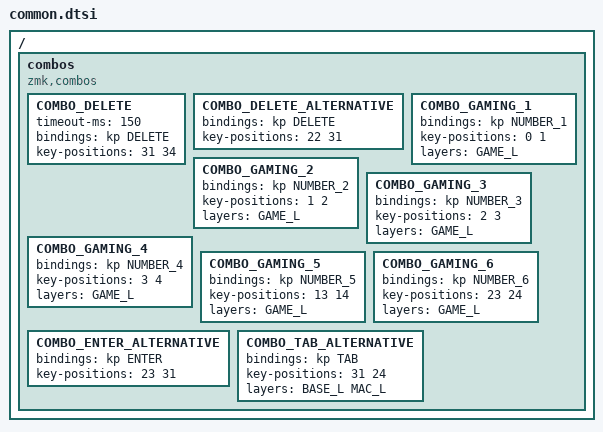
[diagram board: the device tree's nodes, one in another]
/ {
	    combos {
        compatible = "zmk,combos";
// ┌─────┬─────┬─────┬─────┬─────┐┌─────┬─────┬─────┬─────┬─────┐
// │  0  │  1  │  2  │  3  │  4  ││  5  │  6  │  7  │  8  │  9  │
// │─────┼─────┼─────┼─────┼─────┤│─────┼─────┼─────┼─────┼─────┤
// │  10 │  11 │  12 │  13 │  14 ││  15 │  16 │  17 │  18 │  19 │
// │─────┼─────┼─────┼─────┼─────┤│─────┤─────┼─────┼─────┼─────┼
// │  20 │  21 │  22 │  23 │  24 ││  25 │  26 │  27 │  28 │  29 │
// └─────┴─────┼─────┼─────┤─────┤│─────│─────┼─────┼─────┴─────┴
//             │  30 │  31 │  32 ││  33 │  34 │  35 │
//             └─────┼─────┼─────││─────│─────┴─────┘
//                     ENCL│  36 ││  37 │ENCR
//                         ┴─────┴┴─────┘                        
        COMBO_DELETE {
            timeout-ms = <150>;
            bindings = <&kp DELETE>;
            key-positions = <31 34>;
        };


// ┌─────┬─────┬─────┬─────┬─────┐┌─────┬─────┬─────┬─────┬─────┐
// │  0  │  1  │  2  │  3  │  4  ││  5  │  6  │  7  │  8  │  9  │
// │─────┼─────┼─────┼─────┼─────┤│─────┼─────┼─────┼─────┼─────┤
// │  10 │  11 │  12 │  13 │  14 ││  15 │  16 │  17 │  18 │  19 │
// │─────┼─────┼─────┼─────┼─────┤│─────┤─────┼─────┼─────┼─────┼
// │  20 │  21 │  22 │  23 │  24 ││  25 │  26 │  27 │  28 │  29 │
// └─────┴─────┼─────┼─────┤─────┤│─────│─────┼─────┼─────┴─────┴
//             │  30 │  31 │  32 ││  33 │  34 │  35 │
//             └─────┼─────┼─────││─────│─────┴─────┘
//                     ENCL│  36 ││  37 │ENCR
//                         ┴─────┴┴─────┘            
        COMBO_DELETE_ALTERNATIVE {
            bindings = <&kp DELETE>;
            key-positions = <22 31>;
        };

// ┌─────┬─────┬─────┬─────┬─────┐┌─────┬─────┬─────┬─────┬─────┐
// │  0  │  1  │  2  │  3  │  4  ││  5  │  6  │  7  │  8  │  9  │
// │─────┼─────┼─────┼─────┼─────┤│─────┼─────┼─────┼─────┼─────┤
// │  10 │  11 │  12 │  13 │  14 ││  15 │  16 │  17 │  18 │  19 │
// │─────┼─────┼─────┼─────┼─────┤│─────┤─────┼─────┼─────┼─────┼
// │  20 │  21 │  22 │  23 │  24 ││  25 │  26 │  27 │  28 │  29 │
// └─────┴─────┼─────┼─────┤─────┤│─────│─────┼─────┼─────┴─────┴
//             │  30 │  31 │  32 ││  33 │  34 │  35 │
//             └─────┼─────┼─────││─────│─────┴─────┘
//                     ENCL│  36 ││  37 │ENCR
//                         ┴─────┴┴─────┘            
        COMBO_GAMING_1 {
            bindings = <&kp NUMBER_1>;
            key-positions = <0 1>;
            layers = <GAME_L>;
        };

// ┌─────┬─────┬─────┬─────┬─────┐┌─────┬─────┬─────┬─────┬─────┐
// │  0  │  1  │  2  │  3  │  4  ││  5  │  6  │  7  │  8  │  9  │
// │─────┼─────┼─────┼─────┼─────┤│─────┼─────┼─────┼─────┼─────┤
// │  10 │  11 │  12 │  13 │  14 ││  15 │  16 │  17 │  18 │  19 │
// │─────┼─────┼─────┼─────┼─────┤│─────┤─────┼─────┼─────┼─────┼
// │  20 │  21 │  22 │  23 │  24 ││  25 │  26 │  27 │  28 │  29 │
// └─────┴─────┼─────┼─────┤─────┤│─────│─────┼─────┼─────┴─────┴
//             │  30 │  31 │  32 ││  33 │  34 │  35 │
//             └─────┼─────┼─────││─────│─────┴─────┘
//                     ENCL│  36 ││  37 │ENCR
//                         ┴─────┴┴─────┘            
        COMBO_GAMING_2 {
            bindings = <&kp NUMBER_2>;
            key-positions = <1 2>;
            layers = <GAME_L>;
        };

// ┌─────┬─────┬─────┬─────┬─────┐┌─────┬─────┬─────┬─────┬─────┐
// │  0  │  1  │  2  │  3  │  4  ││  5  │  6  │  7  │  8  │  9  │
// │─────┼─────┼─────┼─────┼─────┤│─────┼─────┼─────┼─────┼─────┤
// │  10 │  11 │  12 │  13 │  14 ││  15 │  16 │  17 │  18 │  19 │
// │─────┼─────┼─────┼─────┼─────┤│─────┤─────┼─────┼─────┼─────┼
// │  20 │  21 │  22 │  23 │  24 ││  25 │  26 │  27 │  28 │  29 │
// └─────┴─────┼─────┼─────┤─────┤│─────│─────┼─────┼─────┴─────┴
//             │  30 │  31 │  32 ││  33 │  34 │  35 │
//             └─────┼─────┼─────││─────│─────┴─────┘
//                     ENCL│  36 ││  37 │ENCR
//                         ┴─────┴┴─────┘            

        COMBO_GAMING_3 {
            bindings = <&kp NUMBER_3>;
            key-positions = <2 3>;
            layers = <GAME_L>;
        };

// ┌─────┬─────┬─────┬─────┬─────┐┌─────┬─────┬─────┬─────┬─────┐
// │  0  │  1  │  2  │  3  │  4  ││  5  │  6  │  7  │  8  │  9  │
// │─────┼─────┼─────┼─────┼─────┤│─────┼─────┼─────┼─────┼─────┤
// │  10 │  11 │  12 │  13 │  14 ││  15 │  16 │  17 │  18 │  19 │
// │─────┼─────┼─────┼─────┼─────┤│─────┤─────┼─────┼─────┼─────┼
// │  20 │  21 │  22 │  23 │  24 ││  25 │  26 │  27 │  28 │  29 │
// └─────┴─────┼─────┼─────┤─────┤│─────│─────┼─────┼─────┴─────┴
//             │  30 │  31 │  32 ││  33 │  34 │  35 │
//             └─────┼─────┼─────││─────│─────┴─────┘
//                     ENCL│  36 ││  37 │ENCR
//                         ┴─────┴┴─────┘            
        COMBO_GAMING_4 {
            bindings = <&kp NUMBER_4>;
            key-positions = <3 4>;
            layers = <GAME_L>;
        };

// ┌─────┬─────┬─────┬─────┬─────┐┌─────┬─────┬─────┬─────┬─────┐
// │  0  │  1  │  2  │  3  │  4  ││  5  │  6  │  7  │  8  │  9  │
// │─────┼─────┼─────┼─────┼─────┤│─────┼─────┼─────┼─────┼─────┤
// │  10 │  11 │  12 │  13 │  14 ││  15 │  16 │  17 │  18 │  19 │
// │─────┼─────┼─────┼─────┼─────┤│─────┤─────┼─────┼─────┼─────┼
// │  20 │  21 │  22 │  23 │  24 ││  25 │  26 │  27 │  28 │  29 │
// └─────┴─────┼─────┼─────┤─────┤│─────│─────┼─────┼─────┴─────┴
//             │  30 │  31 │  32 ││  33 │  34 │  35 │
//             └─────┼─────┼─────││─────│─────┴─────┘
//                     ENCL│  36 ││  37 │ENCR
//                         ┴─────┴┴─────┘            

        COMBO_GAMING_5 {
            bindings = <&kp NUMBER_5>;
            key-positions = <13 14>;
            layers = <GAME_L>;
        };

// ┌─────┬─────┬─────┬─────┬─────┐┌─────┬─────┬─────┬─────┬─────┐
// │  0  │  1  │  2  │  3  │  4  ││  5  │  6  │  7  │  8  │  9  │
// │─────┼─────┼─────┼─────┼─────┤│─────┼─────┼─────┼─────┼─────┤
// │  10 │  11 │  12 │  13 │  14 ││  15 │  16 │  17 │  18 │  19 │
// │─────┼─────┼─────┼─────┼─────┤│─────┤─────┼─────┼─────┼─────┼
// │  20 │  21 │  22 │  23 │  24 ││  25 │  26 │  27 │  28 │  29 │
// └─────┴─────┼─────┼─────┤─────┤│─────│─────┼─────┼─────┴─────┴
//             │  30 │  31 │  32 ││  33 │  34 │  35 │
//             └─────┼─────┼─────││─────│─────┴─────┘
//                     ENCL│  36 ││  37 │ENCR
//                         ┴─────┴┴─────┘            
        COMBO_GAMING_6 {
            bindings = <&kp NUMBER_6>;
            key-positions = <23 24>;
            layers = <GAME_L>;
        };

// ┌─────┬─────┬─────┬─────┬─────┐┌─────┬─────┬─────┬─────┬─────┐
// │  0  │  1  │  2  │  3  │  4  ││  5  │  6  │  7  │  8  │  9  │
// │─────┼─────┼─────┼─────┼─────┤│─────┼─────┼─────┼─────┼─────┤
// │  10 │  11 │  12 │  13 │  14 ││  15 │  16 │  17 │  18 │  19 │
// │─────┼─────┼─────┼─────┼─────┤│─────┤─────┼─────┼─────┼─────┼
// │  20 │  21 │  22 │  23 │  24 ││  25 │  26 │  27 │  28 │  29 │
// └─────┴─────┼─────┼─────┤─────┤│─────│─────┼─────┼─────┴─────┴
//             │  30 │  31 │  32 ││  33 │  34 │  35 │
//             └─────┼─────┼─────││─────│─────┴─────┘
//                     ENCL│  36 ││  37 │ENCR
//                         ┴─────┴┴─────┘            

        COMBO_ENTER_ALTERNATIVE {
            bindings = <&kp ENTER>;
            key-positions = <23 31>;
        };

// ┌─────┬─────┬─────┬─────┬─────┐┌─────┬─────┬─────┬─────┬─────┐
// │  0  │  1  │  2  │  3  │  4  ││  5  │  6  │  7  │  8  │  9  │
// │─────┼─────┼─────┼─────┼─────┤│─────┼─────┼─────┼─────┼─────┤
// │  10 │  11 │  12 │  13 │  14 ││  15 │  16 │  17 │  18 │  19 │
// │─────┼─────┼─────┼─────┼─────┤│─────┤─────┼─────┼─────┼─────┼
// │  20 │  21 │  22 │  23 │  24 ││  25 │  26 │  27 │  28 │  29 │
// └─────┴─────┼─────┼─────┤─────┤│─────│─────┼─────┼─────┴─────┴
//             │  30 │  31 │  32 ││  33 │  34 │  35 │
//             └─────┼─────┼─────││─────│─────┴─────┘
//                     ENCL│  36 ││  37 │ENCR
//                         ┴─────┴┴─────┘            

        COMBO_TAB_ALTERNATIVE {
            bindings = <&kp TAB>;
            key-positions = <31 24>;
            layers = <BASE_L MAC_L>;

        };
    };
};

// ┌─────┬─────┬─────┬─────┬─────┐┌─────┬─────┬─────┬─────┬─────┐
// │  0  │  1  │  2  │  3  │  4  ││  5  │  6  │  7  │  8  │  9  │
// │─────┼─────┼─────┼─────┼─────┤│─────┼─────┼─────┼─────┼─────┤
// │  10 │  11 │  12 │  13 │  14 ││  15 │  16 │  17 │  18 │  19 │
// │─────┼─────┼─────┼─────┼─────┤│─────┤─────┼─────┼─────┼─────┼
// │  20 │  21 │  22 │  23 │  24 ││  25 │  26 │  27 │  28 │  29 │
// └─────┴─────┼─────┼─────┤─────┤│─────│─────┼─────┼─────┴─────┴
//             │  30 │  31 │  32 ││  33 │  34 │  35 │
//             └─────┼─────┼─────││─────│─────┴─────┘
//                     ENCL│  36 ││  37 │ENCR
//                         ┴─────┴┴─────┘            
